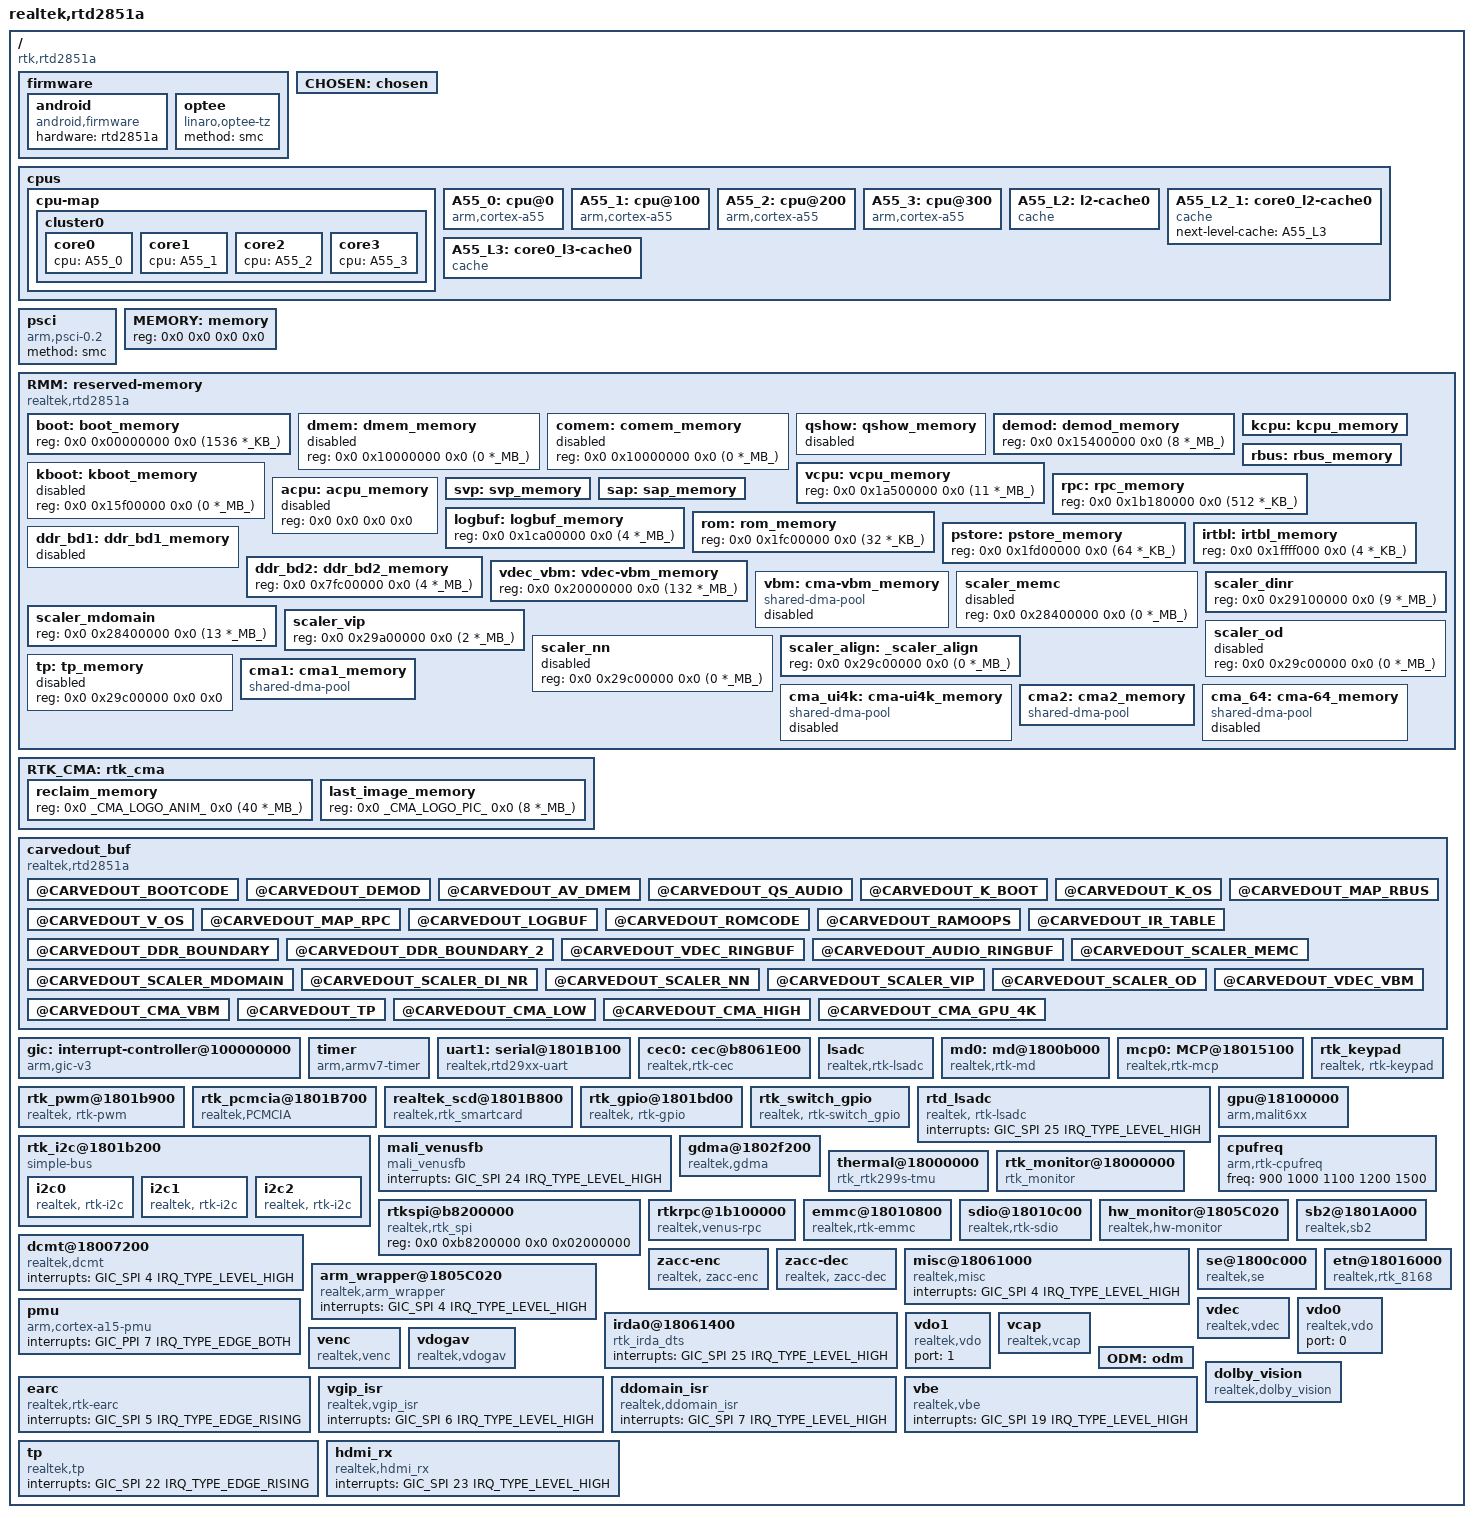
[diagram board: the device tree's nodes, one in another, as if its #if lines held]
/*
 * rtd2851a device tree source
 *
*/

#include <dt-bindings/interrupt-controller/irq.h>
#include <dt-bindings/interrupt-controller/arm-gic.h>

#include <rtk-dt-binding_chip/rtk_kdriver/rmm/rmm_carvedout.h>
#include <rtk-dt-binding_linux/generated/autoconf.h>

/dts-v1/;
/include/ "skeleton.dtsi"
#include "rtk_usb_2851a.dtsi"
#include "rtd2851a_otp_table.dtsi"

#define _KB_      1024
#define _MB_ 1024*1024

/* define cma1 from end to specified size ahead, and boottime borrowed regions */
#define _CMA_LO_SIZE_       (128 * _MB_)
#define _CMA_LO_END_        (0x10000000) //0x0b800000
#define _CMA_LO_START_      (_CMA_LO_END_ - _CMA_LO_SIZE_)  // cma1 region

#define _CMA_LOGO_ANIM_     (_CMA_LO_START_ + 0   *_MB_)    // anim //(0x03800000)
#define _CMA_LOGO_PIC_      (_CMA_LO_START_ + 64  *_MB_)    // pic  //(0x0a000000)


/ {
	model = "realtek,rtd2851a";
	compatible = "rtk,rtd2851a";
	interrupt-parent = <&gic>;
        #address-cells = <2>;
        #size-cells = <2>;

        firmware {
            android {
                    compatible = "android,firmware";
                    hardware = "rtd2851a";
            };
        };

	CHOSEN: chosen {
		bootargs = "earlycon ";
		stdout-path = &uart1;
	};

	cpus {
		#address-cells = <0x1>;
		#size-cells = <0>;

		cpu-map {
			cluster0: cluster0 {
				#cooling-cells = <2>; /* min followed by max */

				core0 {
					cpu = <&A55_0>;
				};
				core1 {
					cpu = <&A55_1>;
				};
				core2 {
					cpu = <&A55_2>;
				};
				core3 {
					cpu = <&A55_3>;
				};
			};

		};

		A55_0: cpu@0 {
			compatible = "arm,cortex-a55","arm,armv8";
			reg = <0x0>;
			device_type = "cpu";
			enable-method = "psci";
                        next-level-cache = <&A55_L2_1>;
			clock-names = "vlittle";
			cpu-release-addr = <0x0 0x500>;
		};
		A55_1: cpu@100 {
			compatible = "arm,cortex-a55","arm,armv8";
			reg = <0x100>;
			device_type = "cpu";
			enable-method = "psci";
                        next-level-cache = <&A55_L2>;
			clock-names = "vlittle";
			cpu-release-addr = <0x0 0x508>;
		};
		A55_2: cpu@200 {
			compatible = "arm,cortex-a55","arm,armv8";
			reg = <0x200>;
			device_type = "cpu";
			enable-method = "psci";
                        next-level-cache = <&A55_L2>;
			clock-names = "vlittle";
			cpu-release-addr = <0x0 0x510>;
		};

		A55_3: cpu@300 {
			compatible = "arm,cortex-a55","arm,armv8";
			reg = <0x300>;
			device_type = "cpu";
			enable-method = "psci";
                        next-level-cache = <&A55_L2>;
			clock-names = "vlittle";
			cpu-release-addr = <0x0 0x518>;
		};

                A55_L2: l2-cache0 {
                        compatible = "cache";
                };

                A55_L2_1: core0_l2-cache0 {
                        compatible = "cache";
                        next-level-cache = <&A55_L3>;
                };

                A55_L3: core0_l3-cache0 {
                        compatible = "cache";
                };
	};

	psci {
		compatible  = "arm,psci-0.2";
		method = "smc";
	};

	MEMORY:memory {
		device_type = "memory";
		reg = <0x0 0x0 0x0 0x0>;
	};

#if defined(RTK_MEM_LAYOUT_DEVICETREE)
	RMM: reserved-memory {
		#address-cells = <2>;
		#size-cells = <2>;
		ranges;

		//! Default REF platform memory layout dts
		//!  there will be other concatenated dtb and overlay dto for different board variants
		compatible = "realtek,rtd2851a";


		boot: boot_memory {                 reg = <0x0 0x00000000 0x0 (1536 *_KB_)>;
		};

		dmem: dmem_memory {                 reg = <0x0 0x10000000 0x0 (0    *_MB_)>;
			status = "disabled";
			/* BAN_NORMAL if size */
		};

		comem: comem_memory {               reg = <0x0 0x10000000 0x0 (0    *_MB_)>;
			status = "disabled";
		};

		qshow: qshow_memory {               reg = <0x0 0x14c00000 0x0 (0    *_MB_)>; // dias
			no-map;
			status = "disabled";
		};

		demod: demod_memory {               reg = <0x0 0x15400000 0x0 (8    *_MB_)>; // tv
			/* BAN_NOT_USED */
		};

		kboot: kboot_memory {               reg = <0x0 0x15f00000 0x0 (0    *_MB_)>;
			status = "disabled"; // it's 0 at rmm.c
		};

		kcpu: kcpu_memory {                 reg = <0x0 0x16000000 0x0 (18   *_MB_)>;
			no-map;
			/* BAN_NOT_USED if ! OPTEE */
		};

		rbus: rbus_memory {                 reg = <0x0 0x18000000 0x0 (2    *_MB_)>; // HW FIXED
			no-map;
		};

		/* for both Video & Audio (Mac7p only) */
		vcpu: vcpu_memory {                 reg = <0x0 0x1a500000 0x0 (11   *_MB_)>; //+1 for quick show
		};

		rpc: rpc_memory {                   reg = <0x0 0x1b180000 0x0 (512  *_KB_)>;
		};

		/* share with vcpu_memory (Mac7p only) */
		acpu: acpu_memory {                 reg = <0x0 0x0 0x0 0x0>;
			status = "disabled";
		};

		// CARVEDOUT_VDEC_RINGBUF
		svp: svp_memory {                   reg = <0x0 0x1b200000 0x0 (16   *_MB_)>;
			no-map;
 		};
		/* Audio OPTEE memory (Mac7p only) */
		sap: sap_memory {                   reg = <0x0 0x1c200000 0x0 (6    *_MB_)>;
			no-map;
 		};

		/*
		 * The maximum reserved space for logbuf
		 *  bootloader can specify smaller size (e.g. 512K) and update loaded fdt to free unused.
		 */
		logbuf: logbuf_memory {             reg = <0x0 0x1ca00000 0x0 (4    *_MB_)>;

			/* rtdlog_get_buffer_size() should be early in kernel */
		};

		rom: rom_memory {                   reg = <0x0 0x1fc00000 0x0 (32   *_KB_)>;
		};

		pstore: pstore_memory {             reg = <0x0 0x1fd00000 0x0 (64   *_KB_)>;
		};

		irtbl: irtbl_memory {               reg = <0x0 0x1ffff000 0x0 (4    *_KB_)>;
		};
		/*
		 * mac7p: it's runtime defined by carvedout_buf_query()
		 * DDR: if 1.5G addr=0x1ffff000, size=0x1000 //1.5g has ddr_swap
		 *      else 0
		 * DDR2: if >=1G size=PAGE_SIZE<<(MAXORDER-1) => 4M
		 *       else PAGE_SIZE => 4K
		 *       addr=DRAM_Size-size !!! at the end of CMA2 !!!
		 *
		 * In legacy rtk_reserve( )
		 * if (CARVEDOUT_DDR_BOUNDARY) memblock_reserve(); // 4KB
		 * if (CARVEDOUT_DDR_END_BOUNDARY == PAGE_SIZE<<(MAXORDER-1)) add_ban_info(BAN_NOT_USED) // if 4MB
		 * else if (PAGE_SIZE) memblock_reserve()); // if 4KB
		 *
		 */
		ddr_bd1: ddr_bd1_memory {           reg = <0x0 0x0 0x0 0x0>;
			status = "disabled";
			no-map;
			/* BAN_NOT_USED if ddr_swap */
		};
		ddr_bd2: ddr_bd2_memory {           reg = <0x0 0x7fc00000 0x0 (4    *_MB_)>;
			/* BAN_NOT_USED if size */
		};

	#if 0
		gal: gal_memory {
			status = "disabled";
			/* BAN_NOT_USED */
		};
	#endif

		// CARVEDOUT_VDEC_VBM
		// (paired with ...CARVEOUT_HEAP_CHUNK_SIZE)
		vdec_vbm: vdec-vbm_memory {         reg = <0x0 0x20000000 0x0 (132  *_MB_)>;
			//no-map; /* mac7p reserved */ // VDEC_VBM(remove), CMA_VBM(reserve) 
		};

		// CARVEDOUT_CMA_VBM
		// (paired with VBM_HEAP_...CHUNK_SIZE)
		vbm: cma-vbm_memory {               reg = <0x0 0x0 0x0 0x0>;
			/* no-map; */ // VDEC_VBM(remove), CMA_VBM(reserve)
			status = "disabled";

			// CARVEDOUT_CMA_VBM
			//! 1. should be shared-dma_pool for native reserve-memory to reserve it for dma/cma
			//! 2. 'xxxx'_memory should be paired with rtkcma_list[ ] name in auth
			compatible = "shared-dma-pool"; // CMA_VBM(reserve)
			reusable;
		};

		scaler_memc: scaler_memc {          reg = <0x0 0x28400000 0x0 (0    *_MB_)>;
			//no-map; /* mac7p reserved */
			status = "disabled";
		};

		scaler_mdomain: scaler_mdomain {    reg = <0x0 0x28400000 0x0 (13   *_MB_)>;
			//no-map; /* mac7p reserved */
		};

		scaler_dinr: scaler_dinr {          reg = <0x0 0x29100000 0x0 (9   *_MB_)>;
			//no-map; /* mac7p reserved */
		};

		scaler_vip: scaler_vip {            reg = <0x0 0x29a00000 0x0 (2    *_MB_)>;
			//no-map; /* mac7p reserved */
		};

		scaler_od: scaler_od {              reg = <0x0 0x29c00000 0x0 (0    *_MB_)>;
			//no-map; /* mac7p reserved */
			status = "disabled";
		};

		scaler_nn: scaler_nn {              reg = <0x0 0x29c00000 0x0 (0    *_MB_)>;
			//no-map; /* mac7p reserved */
			status = "disabled";
		};
		scaler_align: _scaler_align {       reg = <0x0 0x29c00000 0x0 (0    *_MB_)>; // ??? legacy rtk_reserve 4MB-aligned ???
		};

		tp: tp_memory {                     reg = <0x0 0x29c00000 0x0 0x0>;
			//no-map; /* mac7p reserved */
			status = "disabled";
		};

		// CARVEDOUT_GPU_RESERVED

		// CARVEDOUT_CMA_LOW

		cma1: cma1_memory {                 reg = <0x0 _CMA_LO_START_ 0x0 _CMA_LO_SIZE_>;
			compatible = "shared-dma-pool";
			reusable;
			linux,cma-default;
		};

		// CARVEDOUT_CMA_HIGH
		// CARVEDOUT_CMA_GPU_4K
		/*
		 * carvedout_buf_query[ CARVEDOUT_GPU_RESERVED ]
		 *  (DRAM_size > 0x60000)  CMA_HIGHMEM_LARGE; //512MB
		 *  (DRAM_size == 0x60000) CMA_HIGHMEM_LARGE; //368MB
		 *  (DRAM_size < 0x60000)  CMA_HIGHMEM_SMALL; //160MB
		 *
		 *  tp_memory end 0x29c00000
		 *  dram      end 0x80000000 : 0x20000000++0x60000000
		 *
		 *  0x29c00000 + 128MB(ZRAM_RESERVED_SIZE) + 512MB(CARVEDOUT_GPU_RESERVED)
		 *  = 0x29c00000 + 0x08000000 + 0x20000000 = 0x51c00000
		 *
		 *  0x80000000 - 0x51c00000 = 0x2e400000 = 740*_MB_
		 */

		/*
		 * if carvedout start < CARVEDOUT_LIMIT(512MB), then NO cma2
		 */

		/*
		 * if UI_4K, CMA_GPU_4K use an exclusive region from original CMA2
		 */
		cma_ui4k: cma-ui4k_memory {         reg = <0x0 0x0 0x0 0x0>;
			compatible = "shared-dma-pool";
			reusable;
			status = "disabled";
		};
		cma2: cma2_memory {                 reg = <0x0 0x51c00000 0x0 (736 *_MB_)>; /* 2e4 - 4(ddr2) */
			/* mac7p
			 *   becuase bd2 defined to be at the end of CMA2, if specify CMA2 to be zone2(Movable) at
			 *   zone_sizes_init, db2 is also need to be considered to be zone2 or the zone0 size will be wrong
			 *   ** for GKI later, CMA2 may not moved to zone2, and it will no long to be a problem.
			 */
			compatible = "shared-dma-pool";
			reusable;
		};
		/*
		 * separate from cma2 if more than 32-bit.
		 * it's not in carvedout_buf but for kernel managed cma regions and will be mapped to rtkcma_list
		 */
		cma_64: cma-64_memory {             reg = <0x0 0x0 0x0 0x0>; // CMA_64
			compatible = "shared-dma-pool";
			reusable;
			status = "disabled";
		};

		// CARVEDOUT_CMA_3
		// CARVEDOUT_CMA_LOW_LIMIT
		// CARVEDOUT_CMA_BW



	};

	//[TODO] for GKI, cma1 region is reserved in the very beginning but will be returned back to buddy after init.
	//         reserve_dvr_memory() may not be loaded and reserves it in time to avoid other driver access.
	//         may need to be more careful on module loading order.

	/*
	 * CMA param
	 */
	RTK_CMA: rtk_cma {
		#address-cells = <2>;
		#size-cells = <2>;

		reclaim_memory {                    reg = <0x0 _CMA_LOGO_ANIM_ 0x0 (40   *_MB_)>;
		};

		last_image_memory {                 reg = <0x0 _CMA_LOGO_PIC_  0x0 (8    *_MB_)>;
		};
	};


	carvedout_buf {
		#address-cells = <1>;
		#size-cells = <0>;

		compatible = "realtek,rtd2851a";
		memory-region = <&MEMORY>;

		/* carvedout idx, refer rmm.h */

		bufnum = < CARVEDOUT_NUM >;

		@CARVEDOUT_BOOTCODE {
			memory-region = "boot_memory";
			reg = < CARVEDOUT_BOOTCODE >;
		};
		@CARVEDOUT_DEMOD {
			memory-region = "demod_memory";
			reg = < CARVEDOUT_DEMOD >;
		};
		@CARVEDOUT_AV_DMEM { /* also CARVEDOUT_VDEC_COMEM (Mac7p only) */
			memory-region = "dmem_memory";
			reg = < CARVEDOUT_AV_DMEM >;
		};
//		@CARVEDOUT_VDEC_COMEM {
//			memory-region = "comem_memory";
//			reg = < CARVEDOUT_VDEC_COMEM >;
//		};
		@CARVEDOUT_QS_AUDIO {
			memory-region = "qshow_memory";
			reg = < CARVEDOUT_QS_AUDIO >;
		};
		@CARVEDOUT_K_BOOT {
			memory-region = "kboot_memory";
			reg = < CARVEDOUT_K_BOOT >;
		};
		@CARVEDOUT_K_OS {
			memory-region = "kcpu_memory";
			reg = < CARVEDOUT_K_OS >;
		};
		@CARVEDOUT_MAP_RBUS {
			memory-region = "rbus_memory";
			reg = < CARVEDOUT_MAP_RBUS >;
		};
		//CARVEDOUT_GPU_FW {
		//};
		@CARVEDOUT_V_OS { /* also CARVEDOUT_AV_OS, CARVEDOUT_A_OS (Mac7p only) */
			memory-region = "vcpu_memory";
			reg = < CARVEDOUT_V_OS >;
		};
		@CARVEDOUT_MAP_RPC {
			memory-region = "rpc_memory";
			reg = < CARVEDOUT_MAP_RPC >;
		};
//		@CARVEDOUT_A_OS {
//			memory-region = "acpu_memory";
//			reg = < CARVEDOUT_A_OS >;
//		};
		@CARVEDOUT_LOGBUF {
			memory-region = "logbuf_memory";
			reg = < CARVEDOUT_LOGBUF >;
		};
		@CARVEDOUT_ROMCODE {
			memory-region = "rom_memory";
			reg = < CARVEDOUT_ROMCODE >;
		};
		@CARVEDOUT_RAMOOPS {
			memory-region = "pstore_memory";
			reg = < CARVEDOUT_RAMOOPS >;
		};
		@CARVEDOUT_IR_TABLE {
			memory-region = "irtbl_memory";
			reg = < CARVEDOUT_IR_TABLE >;
		};

		@CARVEDOUT_DDR_BOUNDARY {
			memory-region = "ddr_bd1_memory";
			reg = < CARVEDOUT_DDR_BOUNDARY >;
		};
		@CARVEDOUT_DDR_BOUNDARY_2 {
			memory-region = "ddr_bd2_memory";
			reg = < CARVEDOUT_DDR_BOUNDARY_2 >;
		};

		@CARVEDOUT_VDEC_RINGBUF {
			memory-region = "svp_memory";
			reg = < CARVEDOUT_VDEC_RINGBUF >;
		};
		@CARVEDOUT_AUDIO_RINGBUF { /* (Mac7p only) */
			memory-region = "sap_memory";
			reg = < CARVEDOUT_AUDIO_RINGBUF >;
		};

		//CARVEDOUT_SCALER

		@CARVEDOUT_SCALER_MEMC {
			memory-region = "scaler_memc";
			reg = < CARVEDOUT_SCALER_MEMC >;
		};
		@CARVEDOUT_SCALER_MDOMAIN {
			memory-region = "scaler_mdomain";
			reg = < CARVEDOUT_SCALER_MDOMAIN >;
		};
		@CARVEDOUT_SCALER_DI_NR {
			memory-region = "scaler_dinr";
			reg = < CARVEDOUT_SCALER_DI_NR >;
		};
		@CARVEDOUT_SCALER_NN {
			memory-region = "scaler_nn";
			reg = < CARVEDOUT_SCALER_NN >;
		};
		@CARVEDOUT_SCALER_VIP {
			memory-region = "scaler_vip";
			reg = < CARVEDOUT_SCALER_VIP >;
		};
		@CARVEDOUT_SCALER_OD {
			memory-region = "scaler_od";
			reg = < CARVEDOUT_SCALER_OD >;
		};

		@CARVEDOUT_VDEC_VBM {
			memory-region = "vdec-vbm_memory";
			reg = < CARVEDOUT_VDEC_VBM>;
		};

		@CARVEDOUT_CMA_VBM {
			memory-region = "cma-vbm_memory";
			reg = < CARVEDOUT_CMA_VBM >;
		};

		@CARVEDOUT_TP {
			memory-region = "tp_memory";
			reg = < CARVEDOUT_TP >;
		};

		@CARVEDOUT_CMA_LOW {
			memory-region = "cma1_memory";
			reg = < CARVEDOUT_CMA_LOW >;
		};

		@CARVEDOUT_CMA_HIGH {
			memory-region = "cma2_memory";
			reg = < CARVEDOUT_CMA_HIGH >;
		};

		@CARVEDOUT_CMA_GPU_4K {
			memory-region = "cma-ui4k_memory";
			reg = < CARVEDOUT_CMA_GPU_4K >;
		};
	};
#endif //RTK_MEM_LAYOUT_DEVICETREE

	firmware {
		optee {
			compatible = "linaro,optee-tz";
			method = "smc";
		};
	};

	gic:interrupt-controller@100000000 {
                compatible = "arm,gic-v3";
                #interrupt-cells = <0x3>;
                #address-cells = <0x2>;
                #size-cells = <0x2>;
                interrupt-controller;
                redistributor-stride = <0x0 0x20000>;
                #redistributor-regions = <1>;
                reg = <0x1 0x00000000 0x0 0x10000>,       // GICD
                      <0x1 0x00040000 0x0 0x200000>;      // GICR
                interrupts = <GIC_PPI 9 (GIC_CPU_MASK_SIMPLE(4) | IRQ_TYPE_LEVEL_LOW)>;
    };

    timer {
    compatible = "arm,armv7-timer";
    interrupts =
        <GIC_PPI 13 (GIC_CPU_MASK_SIMPLE(4) | IRQ_TYPE_LEVEL_LOW)>,
        <GIC_PPI 14 (GIC_CPU_MASK_SIMPLE(4) | IRQ_TYPE_LEVEL_LOW)>,
        <GIC_PPI 11 (GIC_CPU_MASK_SIMPLE(4) | IRQ_TYPE_LEVEL_LOW)>,
        <GIC_PPI 10 (GIC_CPU_MASK_SIMPLE(4) | IRQ_TYPE_LEVEL_LOW)>;
      clock-frequency = <27000000>;
      always-on = "true";
    };

	uart1: serial@1801B100 {
        	#address-cells = <2>;
        	#size-cells = <2>;
		reg-shift = <2>;
		reg-io-width = <4>;
		compatible = "realtek,rtd29xx-uart", "ns16550";
		reg = <0x00000000 0x1801B100 0x00000000 0x1000>;
		interrupts = <GIC_SPI 25 IRQ_TYPE_LEVEL_HIGH>,
				   <GIC_SPI 19 IRQ_TYPE_LEVEL_HIGH>;
	};

	cec0: cec@b8061E00 {
		compatible = "realtek,rtk-cec";
		reg = <0x00000000 0x18061E00 0x00000000 0x1000>;
		interrupts = <GIC_SPI 25 IRQ_TYPE_LEVEL_HIGH>;
	};


    lsadc {
        compatible = "realtek,rtk-lsadc";
        reg = <0x00000000 0x18061500 0x00000000 0x100>;
        interrupts = <GIC_SPI 25 IRQ_TYPE_LEVEL_HIGH>;
    };

    md0:md@1800b000 {
            compatible = "realtek,rtk-md";
            reg = <0x00000000 0x1800b000 0x00000000 0x230>;
            interrupts = <GIC_SPI 13 IRQ_TYPE_LEVEL_HIGH>;
    };

    mcp0:MCP@18015100 {
            compatible = "realtek,rtk-mcp";
            reg = <0x00000000 0x18015100 0x00000000 0x1000>;
            interrupts = <GIC_SPI 12 IRQ_TYPE_LEVEL_HIGH>;
    };


	rtk_pwm@1801b900 {
		compatible = "realtek, rtk-pwm";
		reg = <0x00000000 0x1801b900 0x00000000 0x194>, //misc pwm
		      <0x00000000 0x18061280 0x00000000 0x34>;  //iso pwm
		interrupts = <GIC_SPI 37 IRQ_TYPE_LEVEL_HIGH>;  //misc pwm int
	};

	rtk_pcmcia@1801B700 {
		compatible = "realtek,PCMCIA";
		reg = <0x00000000 0x1801B700 0x00000000 0x24>;
		interrupts = <GIC_SPI 19 IRQ_TYPE_LEVEL_HIGH>;//IRQ_TYPE_EDGE_BOTH
	};

	realtek_scd@1801B800 {
		compatible = "realtek,rtk_smartcard";
		reg = <0x00000000 0x1801B800 0x00000000 0x7C>;
		interrupts = <GIC_SPI 19 IRQ_TYPE_LEVEL_HIGH>;//IRQ_TYPE_EDGE_BOTH
	};

	rtk_gpio@1801bd00 {
		compatible = "realtek, rtk-gpio";
		reg = <0x00000000 0x1801bd00 0x00000000 0xc0>, //misc gpio
		      <0x00000000 0x18061100 0x00000000 0x4c>;
		interrupts = <GIC_SPI 33 IRQ_TYPE_LEVEL_HIGH>,  //misc gpio int Only mac7p is 33 other is 19*/
			     <GIC_SPI 25 IRQ_TYPE_LEVEL_HIGH>;  //iso gpio int*/
	};

	rtk_switch_gpio {
		compatible = "realtek, rtk-switch_gpio";
	};

	rtk_keypad {
		compatible = "realtek, rtk-keypad";
	};

	rtd_lsadc {
		compatible = "realtek, rtk-lsadc";
		interrupts = <GIC_SPI 25 IRQ_TYPE_LEVEL_HIGH>;
	};

	rtk_i2c@1801b200 {
		compatible = "simple-bus";
		reg = <0x00000000 0x1801b200 0x00000000 0x3fc>, //misc i2c
		      <0x00000000 0x18062500 0x00000000 0x1fc>; //iso i2c
		i2c0{
			compatible = "realtek, rtk-i2c";
			interrupts = <GIC_SPI 25 IRQ_TYPE_LEVEL_HIGH>; //iso irq
			pcb_info = <0 0 0 1>;   //logical_id:0, i2c_mode:0.hw_i2c   phy_id, src
						//                       1.gpio_i2c sda,    scl
		};
		i2c1{
			compatible = "realtek, rtk-i2c";
			interrupts = <GIC_SPI 19 IRQ_TYPE_LEVEL_HIGH>; //misc irq
			pcb_info = <1 0 1 2>;   //logical_id:1, i2c_mode:0.hw_i2c   phy_id, src
						//                       1.gpio_i2c sda,    scl
		};
		i2c2{
			compatible = "realtek, rtk-i2c";
			interrupts = <GIC_SPI 19 IRQ_TYPE_LEVEL_HIGH>; //misc irq
			pcb_info = <2 0 2 0>;   //logical_id2:, i2c_mode:0.hw_i2c   phy_id, src
						//                       1.gpio_i2c sda,    scl
		};
	};


	gpu@18100000{
		compatible = "arm,malit6xx", "arm,mali-midgard";
		reg = <0x00000000 0x18100000 0x00000000 0x4000>;
		interrupts = <GIC_SPI 44 IRQ_TYPE_LEVEL_HIGH>,
				   <GIC_SPI 42 IRQ_TYPE_LEVEL_HIGH>,
				   <GIC_SPI 14 IRQ_TYPE_LEVEL_HIGH>;
		interrupt-names = "JOB", "MMU", "GPU";
		//clocks = <&pclk_mali>;
		//clocks = <10M>
		clock-names = "clk_mali";
	};

	mali_venusfb {
		compatible = "mali_venusfb";
		interrupts = <GIC_SPI 24 IRQ_TYPE_LEVEL_HIGH>;
	};


    gdma@1802f200 {
        #address-cells = <2>;
        #size-cells = <2>;
        device_type = "osd";
        compatible = "realtek,gdma";
        reg = <0x00000000 0x1802f200 0x00000000 0xe00>;
        interrupts = <GIC_SPI 7 IRQ_TYPE_LEVEL_HIGH>;
    };

	cpufreq {
			compatible = "arm,rtk-cpufreq";
			freq = <900 1000 1100 1200 1500>;
	};

	thermal@18000000 {
		#address-cells = <2>;
                #size-cells = <2>;
        	compatible = "rtk_rtk299s-tmu";
        	reg = <0 0x18000000 0 0x400>;
		interrupts = <GIC_SPI 41 IRQ_TYPE_LEVEL_HIGH>;
        	status = "okay";
		throttle = <90 100 120 140>;
        };

        rtk_monitor@18000000 {
                compatible = "rtk_monitor";
                status = "okay";
        };

	rtkspi@b8200000 {
		#address-cells = <2>;
                #size-cells = <2>;
		compatible = "realtek,rtk_spi";
		reg = <0x0 0xb8200000 0x0 0x02000000>;
        };

//	spi0@b8200000 {
//		compatible = "realtek,rtk_spi_master";
//		reg = <0x0 0xb8200000 0x0 0x02000000>;
//		status = "okay";
//		#address-cells = <1>;
//		#size-cells = <0>;  
//		spidev@0 {
//			compatible = "fcic,fcic_spi";
//			spi-max-frequency = <16000000>;
//			reg = <0x0>;
//		};
//	};

	rtkrpc@1b100000 {
	        compatible = "realtek,venus-rpc";
	        reg = <0x0 0x1b100000 0x0 0x00100000>;
	        interrupts = <GIC_SPI 3 IRQ_TYPE_LEVEL_HIGH>;
    	};

	emmc@18010800 {
		compatible = "realtek,rtk-emmc";
		reg = <0x00000000 0x18010800 0x00000000 0x400>;
		interrupts = <GIC_SPI 18 IRQ_TYPE_LEVEL_HIGH>;
	};

	sdio@18010c00 {
		compatible = "realtek,rtk-sdio";
		reg = <0x00000000 0x18010c00 0x00000000 0x400>;
		interrupts = <GIC_SPI 18 IRQ_TYPE_LEVEL_HIGH>;
		bus-width = <4>;
		max-frequency = <37000000>;
		cap-sd-highspeed;
		cap-mmc-hw-reset;
		broken-cd;
	};

	hw_monitor@1805C020 {
		compatible = "realtek,hw-monitor";
	};

	dcmt@18007200 {
		compatible = "realtek,dcmt";
		interrupts = <GIC_SPI 4 IRQ_TYPE_LEVEL_HIGH>;
	};

	sb2@1801A000 {
		compatible = "realtek,sb2";
		interrupts = <GIC_SPI 4 IRQ_TYPE_LEVEL_HIGH>,
				   <GIC_SPI 3 IRQ_TYPE_LEVEL_HIGH>;
		interrupt-names = "SB2_INT",
			"SW_INT";
	};

	zacc-enc{
		compatible = "realtek, zacc-enc";
	};

	zacc-dec{
		compatible = "realtek, zacc-dec";
	};

	misc@18061000 {
		compatible = "realtek,misc";
		interrupts = <GIC_SPI 4 IRQ_TYPE_LEVEL_HIGH>;
	};

	arm_wrapper@1805C020 {
		compatible = "realtek,arm_wrapper";
		interrupts = <GIC_SPI 4 IRQ_TYPE_LEVEL_HIGH>;
	};

	irda0@18061400 {
		compatible = "rtk_irda_dts";
		interrupts = <GIC_SPI 25 IRQ_TYPE_LEVEL_HIGH>;
		//interrupts = < 0 31 0 >;
	};

       se@1800c000 {
                #address-cells = <2>;
                #size-cells = <2>;
                device_type = "2dgraphic";
                compatible = "realtek,se";
                reg = <0x00000000 0x1800c000 0x00000000 0xf00>;
                interrupts = <GIC_SPI 11 IRQ_TYPE_LEVEL_HIGH>;
        };

	etn@18016000 {
		compatible = "realtek,rtk_8168";
		reg = <0x00000000 0x18016000 0x00000000 0x1000>;
		interrupts = <GIC_SPI 20 IRQ_TYPE_LEVEL_HIGH>;
	};

//        clock-controller@0x18000350 {
//               compatible = "realtek,rtd299s-clock";
//                reg = <0x18000350 0x4b0>;
//                #clock-cells = <1>;
//        };

	pmu {
		compatible = "arm,cortex-a15-pmu";
//		interrupts = <GIC_SPI 31 IRQ_TYPE_EDGE_BOTH>;
		interrupts = <GIC_PPI  7 IRQ_TYPE_EDGE_BOTH>; // PPI 23
	};

//    dsu-pmu-0 {
//        compatible = "arm,dsu-pmu";
//        interrupts = <GIC_SPI 30 IRQ_TYPE_LEVEL_HIGH>;
//        cpus = <&A55_0>, <&A55_1>, <&A55_2>, <&A55_3>;
//    };


	vdec {
		compatible = "realtek,vdec";
	};

	vdo0 {
		compatible = "realtek,vdo";
		port = <0>;
	};

	vdo1 {
		compatible = "realtek,vdo";
		port = <1>;
	};

	vcap {
		compatible = "realtek,vcap";
	};

	venc {
		compatible = "realtek,venc";
	};

        vdogav {
                compatible = "realtek,vdogav";
        };
        ODM:odm{
        };
	earc{
		compatible = "realtek,rtk-earc";
		interrupts = <GIC_SPI 5 IRQ_TYPE_EDGE_RISING>;
	};		


        vgip_isr {
                compatible = "realtek,vgip_isr";
                interrupts = <GIC_SPI 6 IRQ_TYPE_LEVEL_HIGH>;
        };

        ddomain_isr {
                compatible = "realtek,ddomain_isr";
                interrupts = <GIC_SPI 7 IRQ_TYPE_LEVEL_HIGH>;
        };

    vbe {
        compatible = "realtek,vbe";
        interrupts = <GIC_SPI 19 IRQ_TYPE_LEVEL_HIGH>;
    };

    tp {
        compatible = "realtek,tp";
        interrupts = <GIC_SPI 22 IRQ_TYPE_EDGE_RISING>;
    };

    hdmi_rx {
        compatible = "realtek,hdmi_rx";
        interrupts = <GIC_SPI 23 IRQ_TYPE_LEVEL_HIGH>;
    };

    dolby_vision {
        compatible = "realtek,dolby_vision";
        interrupts = <GIC_SPI 3 IRQ_TYPE_LEVEL_HIGH>,
                     <GIC_SPI 19 IRQ_TYPE_LEVEL_HIGH>;
	interrupt-names = "SOFTWARE_IRQ",
                          "MISC_IRQ";
    };
};

#if defined(RTK_MEM_LAYOUT_DEVICETREE)

// multiple layouts

#undef LAYOUTNUM
#define LAYOUTNUM	1
#include "rtd2851a/rtd2851a_0_2g.dtsi"

#undef LAYOUTNUM
#define LAYOUTNUM	2
#include "rtd2851a/rtd2851a_1_1g5.dtsi"

#undef LAYOUTNUM
#define LAYOUTNUM	3
#include "rtd2851a/rtd2851a_2_1g.dtsi"

#undef LAYOUTNUM
#define LAYOUTNUM	4
#include "rtd2851a/rtd2851a_3_2k.dtsi"

#endif //RTK_MEM_LAYOUT_DEVICETREE
